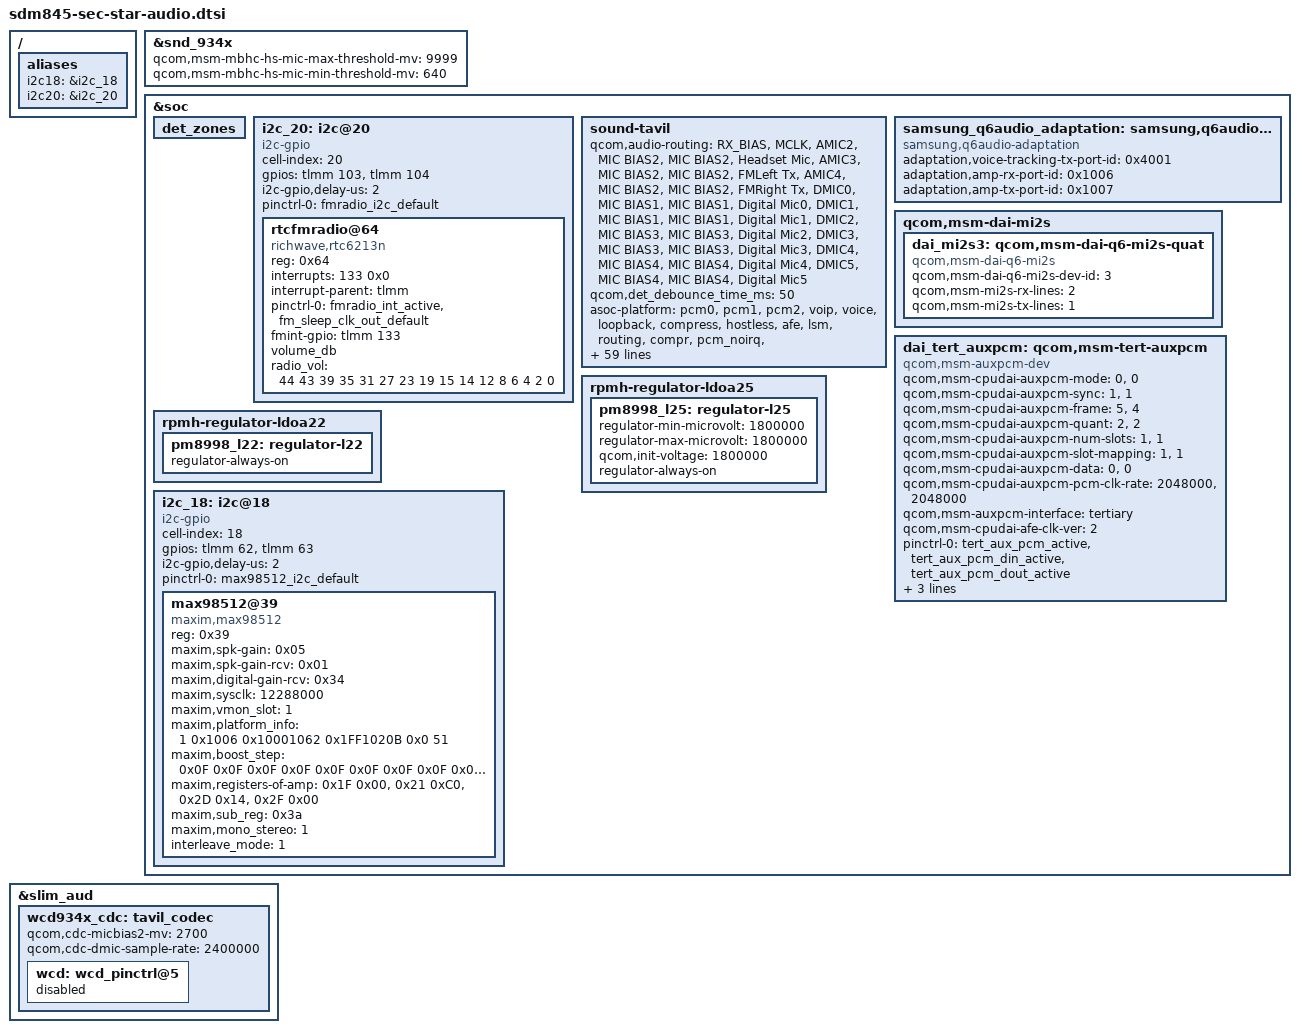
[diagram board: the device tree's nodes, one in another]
/* Copyright (c) 2016-2017, The Linux Foundation. All rights reserved.
 *
 * This program is free software; you can redistribute it and/or modify
 * it under the terms of the GNU General Public License version 2 and
 * only version 2 as published by the Free Software Foundation.
 *
 * This program is distributed in the hope that it will be useful,
 * but WITHOUT ANY WARRANTY; without even the implied warranty of
 * MERCHANTABILITY or FITNESS FOR A PARTICULAR PURPOSE.  See the
 * GNU General Public License for more details.
 */

#include "../qcom/sdm845-audio-overlay.dtsi"
#include "sdm845-sec-star-audio-pinctrl.dtsi"

/{
	aliases {
		i2c18 = &i2c_18;
		i2c20 = &i2c_20;
	};
};

&snd_934x {
	qcom,msm-mbhc-hs-mic-max-threshold-mv = <9999>;
	qcom,msm-mbhc-hs-mic-min-threshold-mv = <640>;
};

&soc {
	det_zones: det_zones {
		#list-det-cells = <2>;
	};

	/delete-node/msm_cdc_pinctrll;
	/delete-node/msm_cdc_pinctrlr;
	/delete-node/msm_cdc_pinctrl_us_euro_sw;
	/delete-node/msm_cdc_pinctrl_hph_en0;
	/delete-node/msm_cdc_pinctrl_hph_en1;
	/delete-node/swr_master;
	/delete-node/msm_cdc_pinctrl@49;

	i2c_20: i2c@20{ /* FM Radio (Richwave) */
		cell-index = <20>;
		compatible = "i2c-gpio";

		gpios = <&tlmm 103 0 /* sda */
			&tlmm 104 0 /* scl */
		>;
		i2c-gpio,delay-us = <2>;
		#address-cells = <1>;
		#size-cells = <0>;
		status = "okay";
		pinctrl-names = "default";
		pinctrl-0 = <&fmradio_i2c_default>;

		rtcfmradio@64 {
			compatible = "richwave,rtc6213n", "rtc6213n";
			reg = <0x64>;
			interrupts = <133 0x0>;
			interrupt-parent = <&tlmm>;
			pinctrl-names = "default";
			pinctrl-0 = <&fmradio_int_active &fm_sleep_clk_out_default>;
			fmint-gpio = <&tlmm 133 0>; /* FM_INT */
			volume_db;
			radio_vol = <44 43 39 35 31 27 23 19
				15 14 12 8 6 4 2 0>;
		};
	};

	sound-tavil {
		/delete-property/qcom,wcn-btfm;

		qcom,audio-routing =
			"RX_BIAS", "MCLK",
			"AMIC2", "MIC BIAS2",
			"MIC BIAS2", "Headset Mic",
			"AMIC3", "MIC BIAS2",
			"MIC BIAS2", "FMLeft Tx",
			"AMIC4", "MIC BIAS2",
			"MIC BIAS2", "FMRight Tx",
			"DMIC0", "MIC BIAS1",
			"MIC BIAS1", "Digital Mic0",
			"DMIC1", "MIC BIAS1",
			"MIC BIAS1", "Digital Mic1",
			"DMIC2", "MIC BIAS3",
			"MIC BIAS3", "Digital Mic2",
			"DMIC3", "MIC BIAS3",
			"MIC BIAS3", "Digital Mic3",
			"DMIC4", "MIC BIAS4",
			"MIC BIAS4", "Digital Mic4",
			"DMIC5", "MIC BIAS4",
			"MIC BIAS4", "Digital Mic5";

		/delete-property/qcom,hph-en0-gpio;
		/delete-property/qcom,hph-en1-gpio;
		/delete-property/qcom,usbc-analog-en1-gpio;
		/delete-property/qcom,usbc-analog-en2-gpio;
		qcom,det_debounce_time_ms = <50>;
		asoc-platform = <&pcm0>, <&pcm1>, <&pcm2>, <&voip>, <&voice>,
				<&loopback>, <&compress>, <&hostless>,
				<&afe>, <&lsm>, <&routing>, <&compr>,
				<&pcm_noirq>, <&samsung_q6audio_adaptation>;
		asoc-platform-names = "msm-pcm-dsp.0", "msm-pcm-dsp.1",
				"msm-pcm-dsp.2", "msm-voip-dsp",
				"msm-pcm-voice", "msm-pcm-loopback",
				"msm-compress-dsp", "msm-pcm-hostless",
				"msm-pcm-afe", "msm-lsm-client",
				"msm-pcm-routing", "msm-compr-dsp",
				"msm-pcm-dsp-noirq", "q6audio-adaptation";
		asoc-cpu = <&dai_hdmi>, <&dai_dp>,
				<&dai_mi2s0>, <&dai_mi2s1>,
				<&dai_mi2s2>, <&dai_mi2s3>,
				<&dai_pri_auxpcm>, <&dai_sec_auxpcm>,
				<&dai_tert_auxpcm>, <&dai_quat_auxpcm>,
				<&sb_0_rx>, <&sb_0_tx>, <&sb_1_rx>, <&sb_1_tx>,
				<&sb_2_rx>, <&sb_2_tx>, <&sb_3_rx>, <&sb_3_tx>,
				<&sb_4_rx>, <&sb_4_tx>, <&sb_5_tx>,
				<&afe_pcm_rx>, <&afe_pcm_tx>, <&afe_proxy_rx>,
				<&afe_proxy_tx>, <&incall_record_rx>,
				<&incall_record_tx>, <&incall_music_rx>,
				<&incall_music_2_rx>, <&sb_5_rx>, <&sb_6_rx>,
				<&sb_7_rx>, <&sb_7_tx>, <&sb_8_tx>,
				<&usb_audio_rx>, <&usb_audio_tx>,
				<&dai_pri_tdm_rx_0>, <&dai_pri_tdm_tx_0>,
				<&dai_sec_tdm_rx_0>, <&dai_sec_tdm_tx_0>,
				<&dai_tert_tdm_rx_0>, <&dai_tert_tdm_tx_0>,
				<&dai_quat_tdm_rx_0>, <&dai_quat_tdm_tx_0>;
		asoc-cpu-names = "msm-dai-q6-hdmi.8",  "msm-dai-q6-dp.24608",
				"msm-dai-q6-mi2s.0", "msm-dai-q6-mi2s.1",
				"msm-dai-q6-mi2s.2", "msm-dai-q6-mi2s.3",
				"msm-dai-q6-auxpcm.1", "msm-dai-q6-auxpcm.2",
				"msm-dai-q6-auxpcm.3", "msm-dai-q6-auxpcm.4",
				"msm-dai-q6-dev.16384", "msm-dai-q6-dev.16385",
				"msm-dai-q6-dev.16386", "msm-dai-q6-dev.16387",
				"msm-dai-q6-dev.16388", "msm-dai-q6-dev.16389",
				"msm-dai-q6-dev.16390", "msm-dai-q6-dev.16391",
				"msm-dai-q6-dev.16392", "msm-dai-q6-dev.16393",
				"msm-dai-q6-dev.16395", "msm-dai-q6-dev.224",
				"msm-dai-q6-dev.225", "msm-dai-q6-dev.241",
				"msm-dai-q6-dev.240", "msm-dai-q6-dev.32771",
				"msm-dai-q6-dev.32772", "msm-dai-q6-dev.32773",
				"msm-dai-q6-dev.32770", "msm-dai-q6-dev.16394",
				"msm-dai-q6-dev.16396", "msm-dai-q6-dev.16398",
				"msm-dai-q6-dev.16399", "msm-dai-q6-dev.16401",
				"msm-dai-q6-dev.28672", "msm-dai-q6-dev.28673",
				"msm-dai-q6-tdm.36864", "msm-dai-q6-tdm.36865",
				"msm-dai-q6-tdm.36880", "msm-dai-q6-tdm.36881",
				"msm-dai-q6-tdm.36896", "msm-dai-q6-tdm.36897",
				"msm-dai-q6-tdm.36912", "msm-dai-q6-tdm.36913";

		pinctrl-names = "quat-mi2s-active", "quat-mi2s-sleep",
				"quat-tdm-active", "quat-tdm-sleep";
		pinctrl-0 = <&quat_mi2s_active &quat_mi2s_sd0_active
					&quat_mi2s_sd1_active>;
		pinctrl-1 = <&quat_mi2s_sleep &quat_mi2s_sd0_sleep
					&quat_mi2s_sd1_sleep>;
		pinctrl-2 = <&quat_tdm_active &quat_tdm_dout_active>;
		pinctrl-3 = <&quat_tdm_sleep &quat_tdm_dout_sleep>;

		mbhc-button-thres = <&det_zones 13 63>,
				 <&det_zones 88 138>,
				 <&det_zones 138 138>,
				 <&det_zones 225 225>,
				 <&det_zones 450 450>,
				 <&det_zones 620 620>,
				 <&det_zones 620 620>,
				 <&det_zones 620 620>;
		/delete-property/qcom,wsa-max-devs;
		/delete-property/qcom,wsa-devs;
		/delete-property/qcom,wsa-aux-dev-prefix;
	};

	samsung_q6audio_adaptation: samsung,q6audio-adaptation {
		compatible = "samsung,q6audio-adaptation";
		adaptation,voice-tracking-tx-port-id = <0x4001>;
		adaptation,amp-rx-port-id = <0x1006>;
		adaptation,amp-tx-port-id = <0x1007>;
	};

	qcom,msm-dai-mi2s {
		dai_mi2s3: qcom,msm-dai-q6-mi2s-quat {
			compatible = "qcom,msm-dai-q6-mi2s";
			qcom,msm-dai-q6-mi2s-dev-id = <3>;
			qcom,msm-mi2s-rx-lines = <2>;
			qcom,msm-mi2s-tx-lines = <1>;
		};
	};

	dai_tert_auxpcm: qcom,msm-tert-auxpcm {
		compatible = "qcom,msm-auxpcm-dev";
		qcom,msm-cpudai-auxpcm-mode = <0>, <0>;
		qcom,msm-cpudai-auxpcm-sync = <1>, <1>;
		qcom,msm-cpudai-auxpcm-frame = <5>, <4>;
		qcom,msm-cpudai-auxpcm-quant = <2>, <2>;
		qcom,msm-cpudai-auxpcm-num-slots = <1>, <1>;
		qcom,msm-cpudai-auxpcm-slot-mapping = <1>, <1>;
		qcom,msm-cpudai-auxpcm-data = <0>, <0>;
		qcom,msm-cpudai-auxpcm-pcm-clk-rate = <2048000>, <2048000>;
		qcom,msm-auxpcm-interface = "tertiary";
		qcom,msm-cpudai-afe-clk-ver = <2>;
		pinctrl-names = "default", "sleep";
		pinctrl-0 = <&tert_aux_pcm_active
			     &tert_aux_pcm_din_active
			     &tert_aux_pcm_dout_active>;
		pinctrl-1 = <&tert_aux_pcm_sleep
			     &tert_aux_pcm_din_sleep
			     &tert_aux_pcm_dout_sleep>;
	};

	rpmh-regulator-ldoa25 {
		pm8998_l25: regulator-l25 {
			/delete-property/qcom,init-mode;
			regulator-min-microvolt = <1800000>;
			regulator-max-microvolt = <1800000>;
			qcom,init-voltage = <1800000>;
			regulator-always-on;
		};
	};

	rpmh-regulator-ldoa22 {
		pm8998_l22: regulator-l22 {
			regulator-always-on;
		};
	};

	i2c_18: i2c@18 {
		cell-index = <18>;
		compatible = "i2c-gpio";
		gpios = <&tlmm 62 0 /* sda */
			&tlmm 63 0 /* scl */
			>;
		i2c-gpio,delay-us = <2>;
		#address-cells = <1>;
		#size-cells = <0>;
		pinctrl-names = "default";
		pinctrl-0 = <&max98512_i2c_default>;

		max98512@39 {
			compatible = "maxim,max98512";
			#sound-dai-cells = <1>;
			reg = <0x39>;
			maxim,spk-gain= <0x05>;  /* 0x05 15dB */
			maxim,spk-gain-rcv = <0x01>; /* 3dB */
			maxim,digital-gain-rcv = <0x34>; /* -3dB */
			maxim,sysclk = <12288000>;
			maxim,vmon_slot = <1>;
			maxim,platform_info = <1 0x1006 0x10001062 0x1FF1020B 0x0 51>;
			maxim,boost_step = <
				0x0F 0x0F 0x0F 0x0F
				0x0F 0x0F 0x0F 0x0F
				0x0F 0x0F 0x0F 0x0F
				0x0F 0x0F 0x02 0x00
				>;
			maxim,registers-of-amp =
				<0x1F 0x00>,
				<0x21 0xC0>,
				<0x2D 0x14>,
				<0x2F 0x00>;
			maxim,sub_reg = <0x3a>;
			maxim,mono_stereo = <1>;
			interleave_mode = <1>;
		};
	};
};

&slim_aud {
	wcd934x_cdc: tavil_codec {
			qcom,cdc-micbias2-mv = <2700>;
			qcom,cdc-dmic-sample-rate = <2400000>;

			wcd: wcd_pinctrl@5 {
				status = "disabled";
			};
			/*qcom,cdc-dmic-clk-drv-strength = <2>;*/
			/delete-node/msm_cdc_pinctrll;
			/delete-node/msm_cdc_pinctrlr;
			/delete-node/msm_cdc_pinctrl_us_euro_sw;
			/delete-node/msm_cdc_pinctrl_hph_en0;
			/delete-node/msm_cdc_pinctrl_hph_en1;
			/delete-node/swr_master;
	};
};

